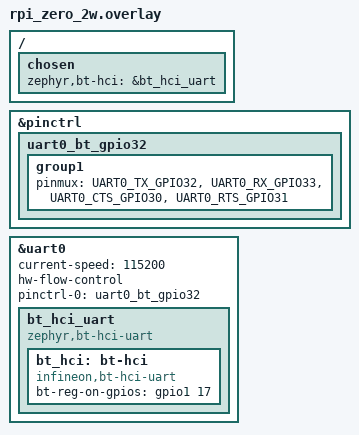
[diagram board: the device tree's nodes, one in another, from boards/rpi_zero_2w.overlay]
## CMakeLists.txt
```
#
# WO-BT-K1 — 8BitDo Micro BT keyboard input on PiZZa Zero 2W.
# Bring-up vehicle / test harness for the Classic BT HID host. The reusable
# capability now lives in apps/lib/btinput (M4.1); this app links it like the
# games link apps/lib/sdl2shim, and keeps only the LE sniffer (hogp.c) and the
# scan/pair/connect orchestration it uses for bring-up.
#
cmake_minimum_required(VERSION 3.20.0)

find_package(Zephyr REQUIRED HINTS $ENV{ZEPHYR_BASE})
project(btk1)

# The BT patchram (.hcd) is a gitignored vendor blob (firmware/PROVENANCE.md).
# Fail the build LOUDLY if it is missing rather than silently emitting an
# empty-patchram image -- at runtime that sends Download_Minidriver with
# nothing to write/launch and wedges the controller. This replaces the need
# for a defensive guard in the upstream Infineon driver.
if(NOT CONFIG_AIROC_CUSTOM_FIRMWARE_HCD_BLOB)
  message(FATAL_ERROR
    "BtK1: CONFIG_AIROC_CUSTOM_FIRMWARE_HCD_BLOB is unset -- point it at a BT patchram .hcd")
endif()
set(_btk1_blob "${CONFIG_AIROC_CUSTOM_FIRMWARE_HCD_BLOB}")
if(NOT IS_ABSOLUTE "${_btk1_blob}")
  set(_btk1_blob "${CMAKE_CURRENT_SOURCE_DIR}/${_btk1_blob}")
endif()
if(NOT EXISTS "${_btk1_blob}")
  message(FATAL_ERROR
    "BtK1: BT patchram not found:\n  ${_btk1_blob}\n"
    "It is gitignored (vendor blob) -- fetch it per firmware/PROVENANCE.md before building.")
endif()

# The Classic HID host + boot keyboard parser: shared library (M4.1).
include(${CMAKE_CURRENT_SOURCE_DIR}/../lib/btinput/btinput.cmake)

# hogp.c (the M3 GATT sniffer) stays on disk as a bring-up tool but is no
# longer compiled -- the lib's LE HOGP backend (CONFIG_BTINPUT_HOGP) is the
# real input path now.
target_sources(app PRIVATE
  src/main.c
  ${BTINPUT_SOURCES}
)

target_include_directories(app PRIVATE ${BTINPUT_INCLUDE_DIRS})
```

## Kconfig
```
# SPDX-License-Identifier: Apache-2.0
#
# WO-BT-K1 harness -- app options. The reusable Classic HID host lives in
# apps/lib/btinput; pull its Kconfig in so CONFIG_BTINPUT (+ its log module)
# is known here, same as the games rsource ../lib/sdl2shim/Kconfig.

rsource "../lib/btinput/Kconfig"

source "Kconfig.zephyr"
```

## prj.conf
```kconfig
# WO-BT-K1 — M2: central + Just Works bonding to the 8BitDo Micro (K mode).
#
# M0 (transport) + M1 (patchram) passed on HW 2026-07-08: SYN43430A1 launches,
# fw local name "BCM43436 37.4MHz Class 1.", ambient adverts at 115200.
# BT debug logging is now OFF: at a 115200 console it dropped ~140 lines
# between prints and drowned both the app output and most adverts.

# The Classic HID host + boot keyboard parser live in apps/lib/btinput (M4.1).
# CONFIG_BTINPUT selects the core Classic-BT pieces (BT, BT_CLASSIC, BT_CENTRAL,
# BT_SMP, BT_BONDABLE). The matching explicit lines below are kept for clarity;
# the board/policy tunables (stack sizes, MAX_CONN/PAIRED, legacy pairing, the
# SD settings backend) are this harness's concern and stay here.
CONFIG_BTINPUT=y
# LE HOGP backend (M4.3): BLE-only HID devices (MX Master 2S mouse). The
# harness's LE scan/connect/security feeds btinput_le_attach().
CONFIG_BTINPUT_HOGP=y

CONFIG_BT=y
CONFIG_BT_OBSERVER=y
CONFIG_BT_CENTRAL=y
CONFIG_BT_GATT_CLIENT=y
# HOGP client (M3): CCC handles found automatically during subscribe.
CONFIG_BT_GATT_AUTO_DISCOVER_CCC=y

# BR/EDR (Classic) host: the pad's keyboard is Classic BT HID -- its BLE face
# (FF10/FF13, stable across fresh pair + reconnects, no HIDS) is the 8BitDo
# app-config channel only. The Mac's name for it ("8BitDo Micro gamepad" vs
# BLE's "80EL") comes from Classic inquiry: dual-mode device, same BD_ADDR.
# EXPERIMENTAL upstream; this controller's firmware does BR/EDR (RPiOS uses it).
CONFIG_BT_CLASSIC=y
CONFIG_BT_DEVICE_NAME="PiZZa"
CONFIG_BT_SMP=y
CONFIG_BT_BONDABLE=y
# M4.3 multi-device: keyboard + mouse concurrently (+ headroom). MAX_PAIRED
# sizes both the LE bond table and the BR link-key pool.
CONFIG_BT_MAX_PAIRED=4
CONFIG_BT_MAX_CONN=3

# Zephyr 4.4 disables LE legacy pairing by default (BT_SMP_SC_PAIR_ONLY=y).
# The 8BitDo Micro's fw is legacy-only SMP (pairing rsp auth_req 0x01: bonding,
# no SC bit -- captured 2026-07-08), so it was rejected at smp.c:3279 with
# AUTH_REQUIREMENTS before any pairing ran. Re-enable legacy: unauthenticated
# Just Works is the WO-accepted trust model for this keypad.
CONFIG_BT_SMP_SC_PAIR_ONLY=n

# Infineon AIROC HCI extension, custom-firmware path.
CONFIG_BT_AIROC=y
CONFIG_BT_AIROC_CUSTOM=y
# Patchram: SYN43430A1 — this unit is the Synaptics 43436S module (wifi side
# runs brcmfmac43436s / "BCM43430A1 7.45.96.s1"), so the BT ROM is 43430A1
# rev. B0-on-A1 launches dead firmware (observed 2026-07-08). See
# firmware/PROVENANCE.md for the RPiOS mapping.
CONFIG_AIROC_CUSTOM_FIRMWARE_HCD_BLOB="firmware/SYN43430A1.hcd"

# Bond persistence: settings FILE backend on the SD FAT — no NVS partition
# (WO T2.2). The identity address also persists there, so the pad bonds to a
# stable identity; bonds and identity live and die together on the card.
CONFIG_BT_SETTINGS=y
CONFIG_SETTINGS=y
CONFIG_SETTINGS_FILE=y
CONFIG_SETTINGS_FILE_PATH="/SD:/bt/settings"

# SD FAT storage (recipe from PizzaShell/Wipeout rpi_zero_2w.conf). MKFS
# stays OFF: a failed mount must degrade to RAM-only bonds, never reformat.
CONFIG_DISK_ACCESS=y
CONFIG_DISK_DRIVERS=y
CONFIG_SDMMC_SUBSYS=y
CONFIG_FILE_SYSTEM=y
CONFIG_FAT_FILESYSTEM_ELM=y
CONFIG_FS_FATFS_LFN=y
CONFIG_FILE_SYSTEM_MKFS=n
CONFIG_FS_FATFS_MOUNT_MKFS=n

CONFIG_LOG=y
CONFIG_BT_LOG_LEVEL_INF=y
# SMP-only debug: shows the Pairing Request/Response feature bytes and the
# exact failure origin (peer vs local) without the firehose of full BT dbg.
CONFIG_BT_SMP_LOG_LEVEL_DBG=y
# (BT_L2CAP_LOG_LEVEL_DBG served its purpose 2026-07-08: the pad's inbound
# bail is a hard ~190 ms deadline that its own mid-auth attempts miss -- no
# SDP query involved; the de-correlated rescue page is the answer. Re-enable
# only for a new L2CAP-level investigation.)

# The 4.2 controller has 1M PHY only; skip the doomed LE Set PHY attempt.
CONFIG_BT_AUTO_PHY_UPDATE=n

# aarch64: the BT stack-size defaults are Cortex-M sized (long WQ 1400,
# RX 1200, HCI TX 512). LE SC pairing runs P-256 on the long workqueue and
# blew straight through it -- instruction abort via a corrupted saved lr,
# ~240 ms after set_security (observed 2026-07-08). Size for 64-bit frames;
# RAM is 256 MB, generosity is free.
CONFIG_BT_LONG_WQ_STACK_SIZE=8192
CONFIG_BT_RX_STACK_SIZE=8192
CONFIG_BT_HCI_TX_STACK_SIZE_WITH_PROMPT=y
CONFIG_BT_HCI_TX_STACK_SIZE=4096
CONFIG_SYSTEM_WORKQUEUE_STACK_SIZE=8192
CONFIG_THREAD_NAME=y

# FATFS + settings frames run on the main thread during init; aarch64 frames
# are wide.
CONFIG_MAIN_STACK_SIZE=8192
```

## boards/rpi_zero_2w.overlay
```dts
/*
 * WO-BT-K1 M0/M1 — route PL011 uart0 to the on-module CYW43436 Bluetooth
 * controller and describe the Infineon AIROC HCI transport.
 *
 * Fixed facts (verified against RPi Linux bcm2708-rpi-bt.dtsi + the Zephyr
 * bcm2711 pinctrl on 2026-07-08):
 *   - BT UART: GPIO 32/33 TXD0/RXD0, GPIO 30/31 CTS0/RTS0, ALT3.
 *   - BT_REG_ON: GPIO 45 (Linux `shutdown-gpios = <&gpio 45>`), which in our
 *     split-bank scheme is bank1 pin 17 (45-28). &gpio1 is already enabled by
 *     the board DTS for WL_REG_ON.
 *   - Console stays on uart1 (mini-UART, GPIO 14/15), so uart0 is free.
 *
 * Baud: current-speed is left at 115200 and fw-download-speed /
 * hci-operation-speed are intentionally omitted, so the driver never re-rates
 * the UART — M0/M1 run entirely at 115200 (WO R1 mitigation). The generic
 * arm,pl011 driver does drive RTS/CTS, so flow control is real at this rate.
 */

#include <zephyr/dt-bindings/gpio/gpio.h>
#include <zephyr/dt-bindings/pinctrl/bcm2711-pinctrl.h>

&pinctrl {
	uart0_bt_gpio32: uart0_bt_gpio32 {
		group1 {
			pinmux = <UART0_TX_GPIO32>, <UART0_RX_GPIO33>,
				 <UART0_CTS_GPIO30>, <UART0_RTS_GPIO31>;
		};
	};
};

&uart0 {
	status = "okay";
	current-speed = <115200>;
	hw-flow-control;
	pinctrl-0 = <&uart0_bt_gpio32>;
	pinctrl-names = "default";

	bt_hci_uart: bt_hci_uart {
		compatible = "zephyr,bt-hci-uart";
		status = "okay";

		bt_hci: bt-hci {
			compatible = "infineon,bt-hci-uart";
			bt-reg-on-gpios = <&gpio1 17 GPIO_ACTIVE_HIGH>;
		};
	};
};

/ {
	chosen {
		/* Points at the OUTER zephyr,bt-hci-uart node (the H:4 driver),
		 * not the inner vendor node. */
		zephyr,bt-hci = &bt_hci_uart;
	};
};
```

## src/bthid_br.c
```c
#include <string.h>

#include <zephyr/kernel.h>
#include <zephyr/sys/printk.h>
#include <zephyr/bluetooth/bluetooth.h>
#include <zephyr/bluetooth/conn.h>
#include <zephyr/bluetooth/l2cap.h>

#include "bthid_br.h"
#include "kbd_report.h"

/* HID profile PSMs (Bluetooth HID v1.1). */
#define PSM_HID_CTRL 0x0011
#define PSM_HID_INTR 0x0013

/* HID transaction header: DATA | Input report. */
#define HID_HDR_DATA_INPUT 0xa1

static struct bt_conn *hid_conn;
static struct kbd_state kbd;

static void hexdump(const char *tag, const uint8_t *p, uint16_t len)
{
	printk("%s (%u):", tag, len);
	for (uint16_t i = 0; i < len; i++) {
		printk(" %02x", p[i]);
	}
	printk("\n");
}

static void key_event(uint8_t usage, bool pressed, void *user_data)
{
	ARG_UNUSED(user_data);
	printk("    KEY 0x%02x %s\n", usage, pressed ? "DOWN" : "UP");
}

/* --- interrupt channel: input reports ------------------------------------ */

static int intr_recv(struct bt_l2cap_chan *chan, struct net_buf *buf)
{
	const uint8_t *d = buf->data;
	uint16_t len = buf->len;

	hexdump("BR-HID INTR", d, len);

	if (len >= 2 && d[0] == HID_HDR_DATA_INPUT) {
		if (len - 1 == KBD_REPORT_LEN) {
			/* Boot-style: [0xA1][8-byte report] */
			kbd_report_process(&kbd, &d[1], KBD_REPORT_LEN,
					   key_event, NULL);
		} else if (len - 2 == KBD_REPORT_LEN) {
			/* Report protocol: [0xA1][report id][8-byte report] */
			printk("  (report id %u)\n", d[1]);
			kbd_report_process(&kbd, &d[2], KBD_REPORT_LEN,
					   key_event, NULL);
		}
	}
	return 0;
}

static int ctrl_recv(struct bt_l2cap_chan *chan, struct net_buf *buf)
{
	hexdump("BR-HID CTRL", buf->data, buf->len);
	return 0;
}

/* --- channel lifecycle ----------------------------------------------------- */

static void intr_connected(struct bt_l2cap_chan *chan)
{
	printk("BR-HID: interrupt channel up -- press EVERY button (keymap "
	       "capture)\n");
}

static void intr_disconnected(struct bt_l2cap_chan *chan)
{
	printk("BR-HID: interrupt channel down\n");
	kbd_report_release_all(&kbd, key_event, NULL);
}

static void ctrl_connected(struct bt_l2cap_chan *chan);
static void ctrl_disconnected(struct bt_l2cap_chan *chan)
{
	printk("BR-HID: control channel down\n");
}

static const struct bt_l2cap_chan_ops intr_ops = {
	.recv = intr_recv,
	.connected = intr_connected,
	.disconnected = intr_disconnected,
};

static const struct bt_l2cap_chan_ops ctrl_ops = {
	.recv = ctrl_recv,
	.connected = ctrl_connected,
	.disconnected = ctrl_disconnected,
};

static struct bt_l2cap_br_chan ctrl_chan;
static struct bt_l2cap_br_chan intr_chan;

static void ctrl_connected(struct bt_l2cap_chan *chan)
{
	int err;

	printk("BR-HID: control channel up; opening interrupt channel\n");

	intr_chan.chan.ops = &intr_ops;
	intr_chan.rx.mtu = 64;

	err = bt_l2cap_chan_connect(hid_conn, &intr_chan.chan, PSM_HID_INTR);
	if (err) {
		printk("BR-HID: interrupt connect failed (%d)\n", err);
	}
}

/* --- inbound path: device-initiated reconnection --------------------------- */

static int hid_server_accept(struct bt_conn *conn,
			     struct bt_l2cap_server *server,
			     struct bt_l2cap_chan **chan)
{
	struct bt_l2cap_br_chan *c = (server->psm == PSM_HID_CTRL)
					     ? &ctrl_chan
					     : &intr_chan;

	if (hid_conn != NULL && hid_conn != conn) {
		return -ENOMEM;
	}

	if (hid_conn == NULL) {
		hid_conn = conn;
		memset(&kbd, 0, sizeof(kbd));
		printk("BR-HID: inbound reconnect (PSM 0x%04x)\n", server->psm);
	}

	/* Accept-callback contract: zero the channel object ourselves. */
	memset(c, 0, sizeof(*c));
	c->chan.ops = (server->psm == PSM_HID_CTRL) ? &ctrl_ops : &intr_ops;
	c->rx.mtu = 64;

	*chan = &c->chan;
	return 0;
}

static struct bt_l2cap_server ctrl_server = {
	.psm = PSM_HID_CTRL,
	.sec_level = BT_SECURITY_L2,
	.accept = hid_server_accept,
};

static struct bt_l2cap_server intr_server = {
	.psm = PSM_HID_INTR,
	.sec_level = BT_SECURITY_L2,
	.accept = hid_server_accept,
};

void bthid_br_register(void)
{
	int err;

	err = bt_l2cap_br_server_register(&ctrl_server);
	err |= bt_l2cap_br_server_register(&intr_server);
	if (err) {
		printk("BR-HID: server register failed\n");
		return;
	}
	printk("BR-HID: PSM 0x11/0x13 servers registered (inbound reconnect)\n");
}

/* --- public entry points ---------------------------------------------------- */

void bthid_br_start(struct bt_conn *conn)
{
	int err;

	/* Safe: while disconnected the stack holds no refs to these. */
	memset(&ctrl_chan, 0, sizeof(ctrl_chan));
	memset(&intr_chan, 0, sizeof(intr_chan));
	memset(&kbd, 0, sizeof(kbd));
	hid_conn = conn;

	ctrl_chan.chan.ops = &ctrl_ops;
	ctrl_chan.rx.mtu = 64;

	/* HID v1.1: control channel first, then interrupt. */
	err = bt_l2cap_chan_connect(conn, &ctrl_chan.chan, PSM_HID_CTRL);
	if (err) {
		printk("BR-HID: control connect failed (%d)\n", err);
		return;
	}
	printk("BR-HID: connecting control channel (PSM 0x11)...\n");
}

void bthid_br_stop(void)
{
	kbd_report_release_all(&kbd, key_event, NULL);
	hid_conn = NULL;
}

bool bthid_br_active(void)
{
	return hid_conn != NULL;
}
```

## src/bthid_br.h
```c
/*
 * WO-BT-K1 — minimal Classic BT (BR/EDR) HID host.
 *
 * The 8BitDo Micro's keyboard lives on the Classic HID profile (its BLE face
 * is the vendor config channel only). Zephyr ships BR/EDR ACL + SSP + L2CAP
 * but no HID host profile; this is the missing ~150 lines: L2CAP PSM 0x11
 * (control) + 0x13 (interrupt), input reports arrive on the interrupt
 * channel as 0xA1-prefixed HID reports.
 */

#ifndef BTHID_BR_H_
#define BTHID_BR_H_

#include <zephyr/bluetooth/conn.h>

/* Register L2CAP servers for PSM 0x11/0x13: bonded HID devices reconnect
 * DEVICE-INITIATED (they page the host and open the channels themselves).
 * Call once after bt_enable, together with bt_br_set_connectable(true).
 */
void bthid_br_register(void);

/* Open the HID control+interrupt channels on a secured BR/EDR connection
 * (host-initiated flow: first pairing, or manual re-page).
 */
void bthid_br_start(struct bt_conn *conn);

/* ACL gone: release held keys, forget channel state. */
void bthid_br_stop(void);

/* True once a HID channel is up or being set up on the current ACL. */
bool bthid_br_active(void);

#endif /* BTHID_BR_H_ */
```

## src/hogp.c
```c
/*
 * WO-BT-K1 M3 — GATT sniffer / input-path discovery.
 *
 * Empirical finding (HW 2026-07-08): the 8BitDo Micro in K mode exposes NO
 * HOGP (0x1812) over BLE -- only GAP, GATT and a vendor service 0xFF10. Its
 * USB keyboard is a separate HID path. So the key data must flow over a
 * vendor characteristic, not HOGP. Rather than assume the format, this
 * sniffs it: enumerate every characteristic, dump readable values, subscribe
 * to every notify/indicate characteristic in the whole DB, and hexdump
 * whatever arrives on a keypress. 8-byte payloads are also run through the
 * boot-keyboard parser in case the vendor pipe carries standard reports.
 */

#include <string.h>

#include <zephyr/kernel.h>
#include <zephyr/sys/printk.h>
#include <zephyr/bluetooth/bluetooth.h>
#include <zephyr/bluetooth/conn.h>
#include <zephyr/bluetooth/gatt.h>
#include <zephyr/bluetooth/uuid.h>

#include "hogp.h"
#include "kbd_report.h"

#define MAX_CHARS 16

struct sniff_char {
	uint16_t value_handle;
	uint8_t props;
	bool is_sc; /* Service Changed (0x2a05) */
	char uuid_str[BT_UUID_STR_LEN];
	bool sub_armed;
	struct bt_gatt_subscribe_params sub;
	struct bt_gatt_discover_params ccc_disc;
};

static void reenumerate(void);

static struct {
	struct bt_conn *conn;
	struct sniff_char chars[MAX_CHARS];
	int n;
	int read_idx;
	struct bt_gatt_discover_params disc;
	struct bt_gatt_read_params read;
	struct kbd_state kbd;
} ctx;

/* --- notifications -------------------------------------------------------- */

static void hexdump(const char *tag, const uint8_t *p, uint16_t len)
{
	printk("%s (%u):", tag, len);
	for (uint16_t i = 0; i < len; i++) {
		printk(" %02x", p[i]);
	}
	printk("\n");
}

static void key_event(uint8_t usage, bool pressed, void *user_data)
{
	ARG_UNUSED(user_data);
	printk("    KEY 0x%02x %s\n", usage, pressed ? "DOWN" : "UP");
}

static uint8_t notify_cb(struct bt_conn *conn,
			 struct bt_gatt_subscribe_params *params,
			 const void *data, uint16_t length)
{
	struct sniff_char *c = CONTAINER_OF(params, struct sniff_char, sub);

	if (data == NULL) {
		printk("NOTIFY handle 0x%04x unsubscribed\n", c->value_handle);
		c->sub_armed = false;
		return BT_GATT_ITER_STOP;
	}

	char tag[64];

	snprintk(tag, sizeof(tag), "NOTIFY 0x%04x %s", c->value_handle, c->uuid_str);
	hexdump(tag, data, length);

	/* A Service Changed indication means the peer's GATT DB just morphed --
	 * this is how the pad would reveal a HID service that wasn't there on
	 * first connect. Re-enumerate to catch it.
	 */
	if (c->is_sc) {
		printk("*** SERVICE CHANGED -- re-enumerating GATT DB ***\n");
		reenumerate();
		return BT_GATT_ITER_CONTINUE;
	}

	/* Speculatively decode as a boot keyboard report. */
	if (length == KBD_REPORT_LEN) {
		kbd_report_process(&ctx.kbd, data, length, key_event, NULL);
	}
	return BT_GATT_ITER_CONTINUE;
}

/* --- read every readable characteristic once (dump static content) -------- */

static void read_next(void);

static uint8_t read_cb(struct bt_conn *conn, uint8_t err,
		       struct bt_gatt_read_params *params,
		       const void *data, uint16_t length)
{
	if (!err && data != NULL) {
		char tag[64];

		snprintk(tag, sizeof(tag), "READ  0x%04x %s",
			 ctx.chars[ctx.read_idx].value_handle,
			 ctx.chars[ctx.read_idx].uuid_str);
		hexdump(tag, data, length);
		return BT_GATT_ITER_CONTINUE;
	}

	ctx.read_idx++;
	read_next();
	return BT_GATT_ITER_STOP;
}

static void read_next(void)
{
	while (ctx.read_idx < ctx.n &&
	       !(ctx.chars[ctx.read_idx].props & BT_GATT_CHRC_READ)) {
		ctx.read_idx++;
	}

	if (ctx.read_idx >= ctx.n) {
		printk("HOGP/sniff: armed. Press EVERY button -- watch for "
		       "NOTIFY lines (that is the keyboard data path).\n");
		return;
	}

	ctx.read.func = read_cb;
	ctx.read.handle_count = 1;
	ctx.read.single.handle = ctx.chars[ctx.read_idx].value_handle;
	ctx.read.single.offset = 0;

	if (bt_gatt_read(ctx.conn, &ctx.read) != 0) {
		ctx.read_idx++;
		read_next();
	}
}

/* --- subscribe to every notify/indicate characteristic ------------------- */

static void subscribe_all(void)
{
	for (int i = 0; i < ctx.n; i++) {
		struct sniff_char *c = &ctx.chars[i];

		if (!(c->props & (BT_GATT_CHRC_NOTIFY | BT_GATT_CHRC_INDICATE))) {
			continue;
		}

		c->sub.notify = notify_cb;
		c->sub.value = (c->props & BT_GATT_CHRC_NOTIFY)
				       ? BT_GATT_CCC_NOTIFY
				       : BT_GATT_CCC_INDICATE;
		c->sub.value_handle = c->value_handle;
		c->sub.ccc_handle = BT_GATT_AUTO_DISCOVER_CCC_HANDLE;
		/* CCC sits right after the value handle; bound the search
		 * tightly so it can't grab a neighbour char's descriptor.
		 */
		c->sub.end_handle = c->value_handle + 2;
		c->sub.disc_params = &c->ccc_disc;
		/* Auto-remove on disconnect so the host never retains these
		 * params past the connection -- otherwise hogp_start's reset
		 * would zero a live subscription and the host would later call
		 * a NULL notify fn (PC=0 crash observed 2026-07-08).
		 */
		atomic_set_bit(c->sub.flags, BT_GATT_SUBSCRIBE_FLAG_VOLATILE);

		int err = bt_gatt_subscribe(ctx.conn, &c->sub);

		if (err && err != -EALREADY) {
			printk("  subscribe 0x%04x failed (%d)\n",
			       c->value_handle, err);
		} else {
			c->sub_armed = true;
			printk("  subscribed 0x%04x %s\n", c->value_handle,
			       c->uuid_str);
		}
	}
}

/* --- characteristic enumeration ------------------------------------------ */

static uint8_t char_cb(struct bt_conn *conn, const struct bt_gatt_attr *attr,
		       struct bt_gatt_discover_params *params)
{
	if (attr == NULL) {
		printk("HOGP/sniff: %d characteristics; subscribing to "
		       "notify/indicate ones\n", ctx.n);
		subscribe_all();
		ctx.read_idx = 0;
		read_next();
		return BT_GATT_ITER_STOP;
	}

	const struct bt_gatt_chrc *chrc = attr->user_data;

	if (ctx.n < MAX_CHARS) {
		struct sniff_char *c = &ctx.chars[ctx.n++];

		c->value_handle = chrc->value_handle;
		c->props = chrc->properties;
		c->is_sc = (bt_uuid_cmp(chrc->uuid, BT_UUID_GATT_SC) == 0);
		bt_uuid_to_str(chrc->uuid, c->uuid_str, sizeof(c->uuid_str));
		printk("  char 0x%04x %s props=0x%02x%s%s%s%s\n",
		       chrc->value_handle, c->uuid_str, chrc->properties,
		       (chrc->properties & BT_GATT_CHRC_READ) ? " RD" : "",
		       (chrc->properties & BT_GATT_CHRC_WRITE) ? " WR" : "",
		       (chrc->properties & BT_GATT_CHRC_NOTIFY) ? " NTF" : "",
		       (chrc->properties & BT_GATT_CHRC_INDICATE) ? " IND" : "");
	}
	return BT_GATT_ITER_CONTINUE;
}

/* --- primary-service enumeration (context) -------------------------------- */

static uint8_t svc_cb(struct bt_conn *conn, const struct bt_gatt_attr *attr,
		      struct bt_gatt_discover_params *params)
{
	if (attr == NULL) {
		/* Now walk every characteristic in the whole DB. */
		ctx.disc.uuid = NULL;
		ctx.disc.func = char_cb;
		ctx.disc.start_handle = BT_ATT_FIRST_ATTRIBUTE_HANDLE;
		ctx.disc.end_handle = BT_ATT_LAST_ATTRIBUTE_HANDLE;
		ctx.disc.type = BT_GATT_DISCOVER_CHARACTERISTIC;

		if (bt_gatt_discover(ctx.conn, &ctx.disc) != 0) {
			printk("HOGP/sniff: char discovery failed\n");
		}
		return BT_GATT_ITER_STOP;
	}

	const struct bt_gatt_service_val *svc = attr->user_data;
	char uuid_str[BT_UUID_STR_LEN];
	bool hids = (bt_uuid_cmp(svc->uuid, BT_UUID_HIDS) == 0);

	bt_uuid_to_str(svc->uuid, uuid_str, sizeof(uuid_str));
	printk("SVC %s handles 0x%04x..0x%04x%s\n", uuid_str, attr->handle,
	       svc->end_handle, hids ? "   <<< HID SERVICE PRESENT >>>" : "");
	return BT_GATT_ITER_CONTINUE;
}

/* --- re-enumerate on Service Changed (catch a dynamic HIDS reveal) -------- */

static struct bt_gatt_discover_params reenum_disc;
static int reenum_count;

static uint8_t reenum_cb(struct bt_conn *conn, const struct bt_gatt_attr *attr,
			 struct bt_gatt_discover_params *params)
{
	if (attr == NULL) {
		printk("=== re-enumeration complete ===\n");
		return BT_GATT_ITER_STOP;
	}

	const struct bt_gatt_service_val *svc = attr->user_data;
	char uuid_str[BT_UUID_STR_LEN];
	bool hids = (bt_uuid_cmp(svc->uuid, BT_UUID_HIDS) == 0);

	bt_uuid_to_str(svc->uuid, uuid_str, sizeof(uuid_str));
	printk("  [re-enum] SVC %s 0x%04x..0x%04x%s\n", uuid_str, attr->handle,
	       svc->end_handle, hids ? "   <<< HID SERVICE APPEARED >>>" : "");
	return BT_GATT_ITER_CONTINUE;
}

static void reenumerate(void)
{
	if (ctx.conn == NULL || reenum_count++ > 8) {
		return;
	}

	reenum_disc.uuid = NULL;
	reenum_disc.func = reenum_cb;
	reenum_disc.start_handle = BT_ATT_FIRST_ATTRIBUTE_HANDLE;
	reenum_disc.end_handle = BT_ATT_LAST_ATTRIBUTE_HANDLE;
	reenum_disc.type = BT_GATT_DISCOVER_PRIMARY;

	if (bt_gatt_discover(ctx.conn, &reenum_disc) != 0) {
		printk("  re-enum discover failed\n");
	}
}

/* --- public entry points -------------------------------------------------- */

void hogp_start(struct bt_conn *conn)
{
	/* Safe to reset now: any prior connection's subscriptions were
	 * volatile and already removed by the host on its disconnect.
	 */
	hogp_stop();
	memset(&ctx, 0, sizeof(ctx));
	ctx.conn = conn;
	reenum_count = 0;

	ctx.disc.uuid = NULL; /* all primary services */
	ctx.disc.func = svc_cb;
	ctx.disc.start_handle = BT_ATT_FIRST_ATTRIBUTE_HANDLE;
	ctx.disc.end_handle = BT_ATT_LAST_ATTRIBUTE_HANDLE;
	ctx.disc.type = BT_GATT_DISCOVER_PRIMARY;

	if (bt_gatt_discover(conn, &ctx.disc) != 0) {
		printk("HOGP/sniff: service discovery failed\n");
		return;
	}
	printk("HOGP/sniff: enumerating GATT DB...\n");
}

void hogp_stop(void)
{
	/* Release keys only. Do NOT memset here -- on disconnect the host may
	 * still be tearing down our (volatile) subscriptions; wiping the
	 * params underneath it is the PC=0 crash. hogp_start does the reset.
	 */
	kbd_report_release_all(&ctx.kbd, key_event, NULL);
}
```

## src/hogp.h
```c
/*
 * WO-BT-K1 M3 — HOGP client: HIDS discovery + input-report subscription.
 */

#ifndef HOGP_H_
#define HOGP_H_

#include <zephyr/bluetooth/conn.h>

/* Kick off HIDS discovery + subscription on an encrypted connection. */
void hogp_start(struct bt_conn *conn);

/* Link gone: release held keys, forget discovered handles. */
void hogp_stop(void);

#endif /* HOGP_H_ */
```

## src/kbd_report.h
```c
/*
 * WO-BT-K1 M3 (T3.3) — boot-format keyboard report diff parser.
 *
 * Pure code: no Zephyr dependencies, so the same file compiles in the
 * native_sim / host unit-test harness (T3.4).
 *
 * Input: 8-byte boot keyboard input reports (modifiers, reserved,
 * 6 keycodes). Key down/up events are derived by diffing consecutive
 * reports; the phantom/rollover report (keycodes all 0x01) is ignored;
 * kbd_report_release_all() synthesizes UP events for everything held
 * (link loss / pad sleep, T4.2).
 */

#ifndef KBD_REPORT_H_
#define KBD_REPORT_H_

#include <stdint.h>
#include <stdbool.h>

#define KBD_REPORT_LEN   8
#define KBD_MAX_KEYS     6

/* Modifier bits are reported as HID usages 0xE0..0xE7 through the same
 * callback as normal keys.
 */
#define KBD_USAGE_MOD_BASE 0xE0

typedef void (*kbd_event_cb_t)(uint8_t usage, bool pressed, void *user_data);

struct kbd_state {
	uint8_t mods;
	uint8_t keys[KBD_MAX_KEYS];
};

/* Process one report; emits down/up events via cb. Returns false if the
 * report was ignored (wrong length or phantom/rollover), true otherwise.
 */
bool kbd_report_process(struct kbd_state *st, const uint8_t *report, int len,
			kbd_event_cb_t cb, void *user_data);

/* Emit UP for every held key/modifier and clear the state. */
void kbd_report_release_all(struct kbd_state *st, kbd_event_cb_t cb,
			    void *user_data);

#endif /* KBD_REPORT_H_ */
```
